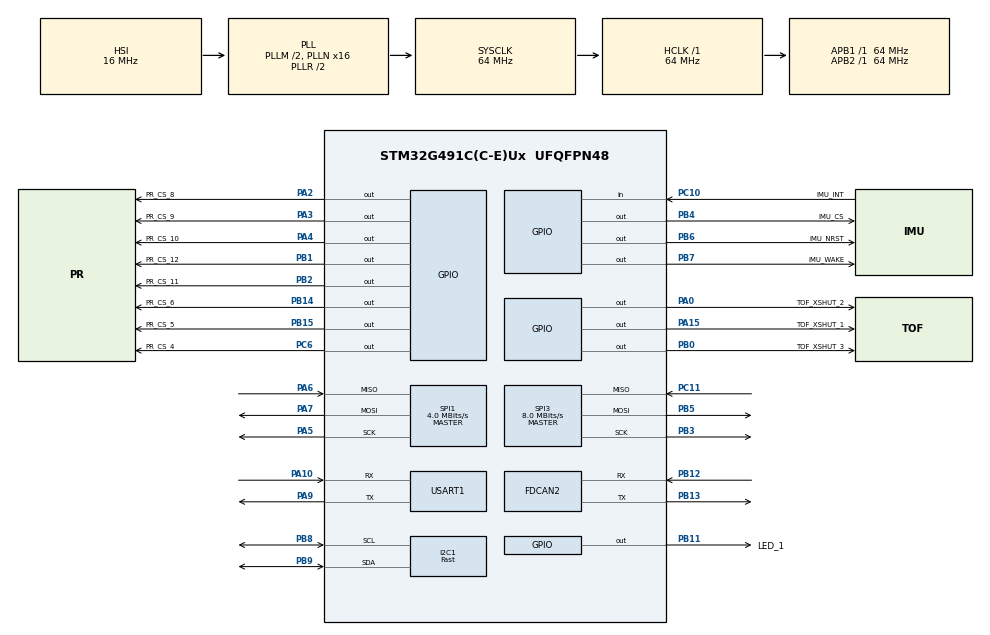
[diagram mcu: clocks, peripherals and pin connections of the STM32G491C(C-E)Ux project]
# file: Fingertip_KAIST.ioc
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FDCAN2.AutoRetransmission=ENABLE
FDCAN2.CalculateBaudRateNominal=500000
FDCAN2.CalculateTimeBitNominal=2000
FDCAN2.CalculateTimeQuantumNominal=250.0
FDCAN2.DataSyncJumpWidth=2
FDCAN2.NominalPrescaler=16
FDCAN2.NominalTimeSeg1=5
FDCAN2.NominalTimeSeg2=2
I2C1.I2C_Fall_Time=0
I2C1.I2C_Rise_Time=0
I2C1.I2C_Speed_Mode=I2C_Fast
I2C1.Timing=0x0010061A
Mcu.Family=STM32G4
Mcu.Name=STM32G491C(C-E)Ux
Mcu.Package=UFQFPN48
NVIC.PriorityGroup=NVIC_PRIORITYGROUP_4
NVIC.TIM2_IRQn=true\:5\:0\:true\:false\:true\:true\:true\:true
NVIC.TIM3_IRQn=true\:5\:0\:true\:false\:true\:true\:true\:true
PA0.GPIO_Label=TOF_XSHUT_2
PA0.Signal=GPIO_Output
PA10.GPIO_Speed=GPIO_SPEED_FREQ_HIGH
PA10.Mode=Asynchronous
PA10.Signal=USART1_RX
PA13.Signal=SYS_JTMS-SWDIO
PA14.Signal=SYS_JTCK-SWCLK
PA15.GPIO_Label=TOF_XSHUT_1
PA15.Signal=GPIO_Output
PA2.GPIO_Label=PR_CS_8
PA2.Signal=GPIO_Output
PA3.GPIO_Label=PR_CS_9
PA3.Signal=GPIO_Output
PA4.GPIO_Label=PR_CS_10
PA4.Signal=GPIO_Output
PA5.GPIO_Speed=GPIO_SPEED_FREQ_HIGH
PA5.Mode=Full_Duplex_Master
PA5.Signal=SPI1_SCK
PA6.GPIO_Speed=GPIO_SPEED_FREQ_HIGH
PA6.Mode=Full_Duplex_Master
PA6.Signal=SPI1_MISO
PA7.GPIO_Speed=GPIO_SPEED_FREQ_HIGH
PA7.Mode=Full_Duplex_Master
PA7.Signal=SPI1_MOSI
PA9.GPIO_Speed=GPIO_SPEED_FREQ_HIGH
PA9.Mode=Asynchronous
PA9.Signal=USART1_TX
PB0.GPIO_Label=TOF_XSHUT_3
PB0.Signal=GPIO_Output
PB1.GPIO_Label=PR_CS_12
PB1.Signal=GPIO_Output
PB11.GPIO_Label=LED_1
PB11.Signal=GPIO_Output
PB12.Mode=FDCAN_Activate
PB12.Signal=FDCAN2_RX
PB13.Mode=FDCAN_Activate
PB13.Signal=FDCAN2_TX
PB14.GPIO_Label=PR_CS_6
PB14.Signal=GPIO_Output
PB15.GPIO_Label=PR_CS_5
PB15.Signal=GPIO_Output
PB2.GPIO_Label=PR_CS_11
PB2.Signal=GPIO_Output
PB3.Mode=Full_Duplex_Master
PB3.Signal=SPI3_SCK
PB4.GPIO_Label=IMU_CS
PB4.Signal=GPIO_Output
PB5.Mode=Full_Duplex_Master
PB5.Signal=SPI3_MOSI
PB6.GPIO_Label=IMU_NRST
PB6.Signal=GPIO_Output
PB7.GPIO_Label=IMU_WAKE
PB7.Signal=GPIO_Output
PB8-BOOT0.GPIO_Speed=GPIO_SPEED_FREQ_HIGH
PB8-BOOT0.Mode=I2C
PB8-BOOT0.Signal=I2C1_SCL
PB9.GPIO_Speed=GPIO_SPEED_FREQ_HIGH
PB9.Mode=I2C
PB9.Signal=I2C1_SDA
PC10.GPIO_Label=IMU_INT
PC10.Signal=GPIO_Input
PC11.Mode=Full_Duplex_Master
PC11.Signal=SPI3_MISO
PC6.GPIO_Label=PR_CS_4
PC6.Signal=GPIO_Output
ProjectManager.HeapSize=0x200
ProjectManager.StackSize=0x400
ProjectManager.TargetToolchain=STM32CubeIDE
RCC.ADC12Freq_Value=64000000
RCC.ADC345Freq_Value=64000000
RCC.AHBFreq_Value=64000000
RCC.APB1Freq_Value=64000000
RCC.APB1TimFreq_Value=64000000
RCC.APB2Freq_Value=64000000
RCC.APB2TimFreq_Value=64000000
RCC.CortexFreq_Value=64000000
RCC.EXTERNAL_CLOCK_VALUE=12288000
RCC.HCLKFreq_Value=64000000
RCC.HSE_VALUE=8000000
RCC.HSI48_VALUE=48000000
RCC.HSI_VALUE=16000000
RCC.I2C1CLockSelection=RCC_I2C1CLKSOURCE_HSI
RCC.LSE_VALUE=32768
RCC.PLLM=RCC_PLLM_DIV2
RCC.PLLN=16
RCC.SYSCLKFreq_VALUE=64000000
RCC.SYSCLKSource=RCC_SYSCLKSOURCE_PLLCLK
RCC.VCOOutputFreq_Value=128000000
SPI1.BaudRatePrescaler=SPI_BAUDRATEPRESCALER_16
SPI1.CalculateBaudRate=4.0 MBits/s
SPI1.DataSize=SPI_DATASIZE_8BIT
SPI1.Direction=SPI_DIRECTION_2LINES
SPI1.Mode=SPI_MODE_MASTER
SPI1.NSSPMode=SPI_NSS_PULSE_DISABLE
SPI1.VirtualType=VM_MASTER
SPI3.BaudRatePrescaler=SPI_BAUDRATEPRESCALER_8
SPI3.CalculateBaudRate=8.0 MBits/s
SPI3.Direction=SPI_DIRECTION_2LINES
SPI3.Mode=SPI_MODE_MASTER
SPI3.VirtualType=VM_MASTER
TIM15.Prescaler=64
TIM2.PeriodNoDither=5000
TIM2.Prescaler=64
TIM3.Prescaler=64
USART1.VirtualMode-Asynchronous=VM_ASYNC
VP_SYS_VS_DBSignals.Mode=DisableDeadBatterySignals
VP_TIM15_VS_ClockSourceINT.Mode=Internal
VP_TIM2_VS_ClockSourceINT.Mode=Internal
VP_TIM3_VS_ClockSourceINT.Mode=Internal
board=custom

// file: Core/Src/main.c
/* USER CODE BEGIN Header */
/**
  ******************************************************************************
  * @file           : main.c
  * @brief          : Main program body
  ******************************************************************************
  * @attention
  *
  * Copyright (c) 2025 STMicroelectronics.
  * All rights reserved.
  *
  * This software is licensed under terms that can be found in the LICENSE file
  * in the root directory of this software component.
  * If no LICENSE file comes with this software, it is provided AS-IS.
  *
  ******************************************************************************
  */
/* USER CODE END Header */
#include "main.h"
#include "fdcan.h"
#include "i2c.h"
#include "spi.h"
#include "tim.h"
#include "usart.h"
#include "gpio.h"

/* USER CODE BEGIN Includes */
#include "fingertip.h"

/* USER CODE END Includes */

void SystemClock_Config(void);

int main(void)
{

  /* MCU Configuration--------------------------------------------------------*/

  /* Reset of all peripherals, Initializes the Flash interface and the Systick. */
  HAL_Init();

  /* Configure the system clock */
  SystemClock_Config();

  /* Initialize all configured peripherals */
  MX_GPIO_Init();
  MX_FDCAN2_Init();
  MX_I2C1_Init();
  MX_SPI1_Init();
  MX_SPI3_Init();
  MX_USART1_UART_Init();
  MX_TIM2_Init();
  MX_TIM3_Init();
  MX_TIM15_Init();

  /* USER CODE BEGIN 2 */
  HAL_TIM_Base_Start_IT(&htim2);
  HAL_TIM_Base_Start(&htim3);
  HAL_TIM_Base_Start(&htim15);

  HAL_NVIC_EnableIRQ(USART1_IRQn);

  /* USER CODE END 2 */

  /* Infinite loop */
  /* USER CODE BEGIN WHILE */
//  if (!(SysTick->CTRL & SysTick_CTRL_ENABLE_Msk)) {
//	  __NOP();
//  }
  fingertip_main();

  while (1)
  {
    /* USER CODE END WHILE */

    /* USER CODE BEGIN 3 */
//	  HAL_Delay(250);
//	  HAL_GPIO_WritePin(LED_1_GPIO_Port, LED_1_Pin, GPIO_PIN_RESET);
//	  for (int i = 0; i < 1000000; i++){}

//	  HAL_Delay(250);
//	  HAL_GPIO_WritePin(LED_1_GPIO_Port, LED_1_Pin, GPIO_PIN_SET);
  }
  /* USER CODE END 3 */
}

void SystemClock_Config(void)
{
  RCC_OscInitTypeDef RCC_OscInitStruct = {0};
  RCC_ClkInitTypeDef RCC_ClkInitStruct = {0};

  /** Configure the main internal regulator output voltage
  */
  HAL_PWREx_ControlVoltageScaling(PWR_REGULATOR_VOLTAGE_SCALE1);

  /** Initializes the RCC Oscillators according to the specified parameters
  * in the RCC_OscInitTypeDef structure.
  */
  RCC_OscInitStruct.OscillatorType = RCC_OSCILLATORTYPE_HSI;
  RCC_OscInitStruct.HSIState = RCC_HSI_ON;
  RCC_OscInitStruct.HSICalibrationValue = RCC_HSICALIBRATION_DEFAULT;
  RCC_OscInitStruct.PLL.PLLState = RCC_PLL_ON;
  RCC_OscInitStruct.PLL.PLLSource = RCC_PLLSOURCE_HSI;
  RCC_OscInitStruct.PLL.PLLM = RCC_PLLM_DIV2;
  RCC_OscInitStruct.PLL.PLLN = 16;
  RCC_OscInitStruct.PLL.PLLP = RCC_PLLP_DIV2;
  RCC_OscInitStruct.PLL.PLLQ = RCC_PLLQ_DIV2;
  RCC_OscInitStruct.PLL.PLLR = RCC_PLLR_DIV2;
  if (HAL_RCC_OscConfig(&RCC_OscInitStruct) != HAL_OK)
  {
    Error_Handler();
  }

  /** Initializes the CPU, AHB and APB buses clocks
  */
  RCC_ClkInitStruct.ClockType = RCC_CLOCKTYPE_HCLK|RCC_CLOCKTYPE_SYSCLK
                              |RCC_CLOCKTYPE_PCLK1|RCC_CLOCKTYPE_PCLK2;
  RCC_ClkInitStruct.SYSCLKSource = RCC_SYSCLKSOURCE_PLLCLK;
  RCC_ClkInitStruct.AHBCLKDivider = RCC_SYSCLK_DIV1;
  RCC_ClkInitStruct.APB1CLKDivider = RCC_HCLK_DIV1;
  RCC_ClkInitStruct.APB2CLKDivider = RCC_HCLK_DIV1;

  if (HAL_RCC_ClockConfig(&RCC_ClkInitStruct, FLASH_LATENCY_2) != HAL_OK)
  {
    Error_Handler();
  }
}

void Error_Handler(void)
{
  __disable_irq();
  while (1)
  {
  }
}
